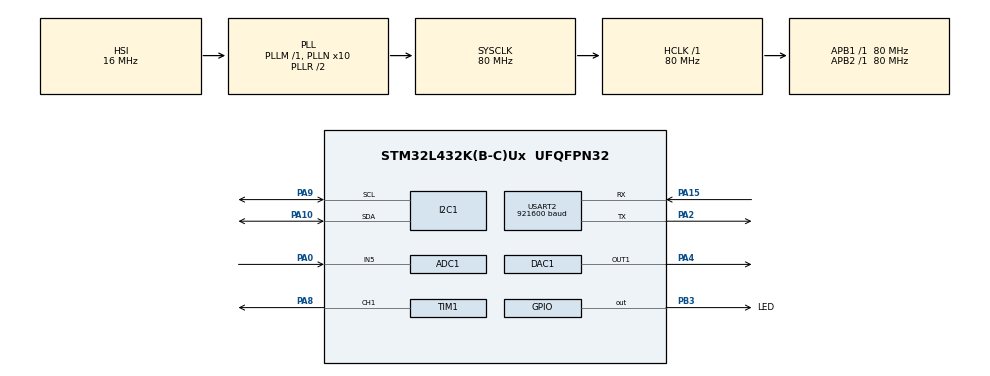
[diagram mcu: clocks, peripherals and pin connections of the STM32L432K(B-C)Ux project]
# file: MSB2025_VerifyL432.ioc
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ADC1.Channel-0\#ChannelRegularConversion=ADC_CHANNEL_5
ADC1.ClockPrescaler=ADC_CLOCK_ASYNC_DIV1
ADC1.ContinuousConvMode=ENABLE
ADC1.NbrOfConversion=1
ADC1.NbrOfConversionFlag=1
ADC1.OffsetNumber-0\#ChannelRegularConversion=ADC_OFFSET_NONE
ADC1.Rank-0\#ChannelRegularConversion=1
ADC1.SamplingTime-0\#ChannelRegularConversion=ADC_SAMPLETIME_47CYCLES_5
ADC1.master=1
DAC1.DAC_OutputBuffer-DAC_OUT1=DAC_OUTPUTBUFFER_DISABLE
DAC1.DAC_Trigger-DAC_OUT1=DAC_TRIGGER_T6_TRGO
Dma.ADC1.0.Direction=DMA_PERIPH_TO_MEMORY
Dma.ADC1.0.Instance=DMA1_Channel1
Dma.ADC1.0.MemDataAlignment=DMA_MDATAALIGN_HALFWORD
Dma.ADC1.0.MemInc=DMA_MINC_ENABLE
Dma.ADC1.0.Mode=DMA_CIRCULAR
Dma.ADC1.0.PeriphDataAlignment=DMA_PDATAALIGN_HALFWORD
Dma.ADC1.0.PeriphInc=DMA_PINC_DISABLE
Dma.ADC1.0.Priority=DMA_PRIORITY_LOW
Dma.DAC_CH1.1.Direction=DMA_MEMORY_TO_PERIPH
Dma.DAC_CH1.1.Instance=DMA2_Channel4
Dma.DAC_CH1.1.MemDataAlignment=DMA_MDATAALIGN_HALFWORD
Dma.DAC_CH1.1.MemInc=DMA_MINC_ENABLE
Dma.DAC_CH1.1.Mode=DMA_CIRCULAR
Dma.DAC_CH1.1.PeriphDataAlignment=DMA_PDATAALIGN_HALFWORD
Dma.DAC_CH1.1.PeriphInc=DMA_PINC_DISABLE
Dma.DAC_CH1.1.Priority=DMA_PRIORITY_LOW
Dma.Request0=ADC1
Dma.Request1=DAC_CH1
I2C1.Timing=0x10909CEC
Mcu.Family=STM32L4
Mcu.Name=STM32L432K(B-C)Ux
Mcu.Package=UFQFPN32
NVIC.ADC1_IRQn=true\:3\:0\:true\:false\:true\:true\:true\:true
NVIC.DMA1_Channel1_IRQn=true\:3\:0\:true\:false\:true\:false\:true\:true
NVIC.DMA2_Channel4_IRQn=true\:3\:0\:true\:false\:true\:false\:true\:true
NVIC.PriorityGroup=NVIC_PRIORITYGROUP_4
NVIC.TIM6_DAC_IRQn=true\:3\:0\:true\:false\:true\:true\:true\:true
PA0.Signal=ADCx_IN5
PA10.Mode=I2C
PA10.Signal=I2C1_SDA
PA13\ (JTMS-SWDIO).Mode=Serial_Wire
PA13\ (JTMS-SWDIO).Signal=SYS_JTMS-SWDIO
PA14\ (JTCK-SWCLK).Mode=Serial_Wire
PA14\ (JTCK-SWCLK).Signal=SYS_JTCK-SWCLK
PA15\ (JTDI).Mode=Asynchronous
PA15\ (JTDI).Signal=USART2_RX
PA2.Mode=Asynchronous
PA2.Signal=USART2_TX
PA4.Signal=COMP_DAC11_group
PA8.Signal=S_TIM1_CH1
PA9.Mode=I2C
PA9.Signal=I2C1_SCL
PB3\ (JTDO-TRACESWO).GPIO_Label=LED
PB3\ (JTDO-TRACESWO).Signal=GPIO_Output
PC14-OSC32_IN\ (PC14).Mode=LSE-External-Oscillator
PC14-OSC32_IN\ (PC14).Signal=RCC_OSC32_IN
PC15-OSC32_OUT\ (PC15).Mode=LSE-External-Oscillator
PC15-OSC32_OUT\ (PC15).Signal=RCC_OSC32_OUT
ProjectManager.HeapSize=0x200
ProjectManager.StackSize=0x400
ProjectManager.TargetToolchain=MDK-ARM V5.32
RCC.ADCFreq_Value=80000000
RCC.AHBFreq_Value=80000000
RCC.APB1Freq_Value=80000000
RCC.APB1TimFreq_Value=80000000
RCC.APB2Freq_Value=80000000
RCC.APB2TimFreq_Value=80000000
RCC.CortexFreq_Value=80000000
RCC.HCLKFreq_Value=80000000
RCC.HSE_VALUE=8000000
RCC.HSI48_VALUE=48000000
RCC.HSI_VALUE=16000000
RCC.MSI_VALUE=4000000
RCC.PLLN=10
RCC.PLLSAI1N=10
RCC.PLLSourceVirtual=RCC_PLLSOURCE_HSI
RCC.SYSCLKFreq_VALUE=80000000
RCC.SYSCLKSource=RCC_SYSCLKSOURCE_PLLCLK
RCC.USBFreq_Value=80000000
RCC.VCOOutputFreq_Value=160000000
SH.ADCx_IN5.0=ADC1_IN5,IN5-Single-Ended
SH.COMP_DAC11_group.0=DAC1_OUT1,DAC_OUT1
SH.S_TIM1_CH1.0=TIM1_CH1,PWM Generation1 CH1
TIM1.Channel-PWM\ Generation1\ CH1=TIM_CHANNEL_1
TIM1.Period=100 - 1
TIM1.Prescaler=8 - 1
TIM1.Pulse-PWM\ Generation1\ CH1=50
TIM6.AutoReloadPreload=TIM_AUTORELOAD_PRELOAD_ENABLE
TIM6.Period=60 - 1
TIM6.Prescaler=4 - 1
TIM6.TIM_MasterOutputTrigger=TIM_TRGO_UPDATE
USART2.BaudRate=921600
USART2.VirtualMode-Asynchronous=VM_ASYNC
VP_TIM1_VS_ClockSourceINT.Mode=Internal
VP_TIM6_VS_ClockSourceINT.Mode=Enable_Timer
board=custom

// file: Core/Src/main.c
/* USER CODE BEGIN Header */
/**
  ******************************************************************************
  * @file           : main.c
  * @brief          : Main program body
  ******************************************************************************
  * @attention
  *
  * Copyright (c) 2025 STMicroelectronics.
  * All rights reserved.
  *
  * This software is licensed under terms that can be found in the LICENSE file
  * in the root directory of this software component.
  * If no LICENSE file comes with this software, it is provided AS-IS.
  *
  ******************************************************************************
  */
/* USER CODE END Header */
#include "main.h"
#include "adc.h"
#include "dac.h"
#include "dma.h"
#include "i2c.h"
#include "tim.h"
#include "usart.h"
#include "gpio.h"

/* USER CODE BEGIN Includes */
#include "tasks.h"
#include "uart.h"
/* USER CODE END Includes */

void SystemClock_Config(void);

int main(void)
{

  /* MCU Configuration--------------------------------------------------------*/

  /* Reset of all peripherals, Initializes the Flash interface and the Systick. */
  HAL_Init();

  /* Configure the system clock */
  SystemClock_Config();

  /* Initialize all configured peripherals */
  MX_GPIO_Init();
  MX_DMA_Init();
  MX_ADC1_Init();
  MX_DAC1_Init();
  MX_I2C1_Init();
  MX_USART2_UART_Init();
  MX_TIM1_Init();
  MX_TIM6_Init();
  /* USER CODE BEGIN 2 */
  startup();
  HAL_TIM_Base_Start(&htim1);
  HAL_TIM_PWM_Start(&htim1, TIM_CHANNEL_1);
  /* USER CODE END 2 */

  /* Infinite loop */
  while (1)
  {

    /* USER CODE BEGIN 3 */
	  // dac_update();
	  HAL_Delay(1000);
  }
  /* USER CODE END 3 */
}

void SystemClock_Config(void)
{
  RCC_OscInitTypeDef RCC_OscInitStruct = {0};
  RCC_ClkInitTypeDef RCC_ClkInitStruct = {0};

  /** Configure the main internal regulator output voltage
  */
  if (HAL_PWREx_ControlVoltageScaling(PWR_REGULATOR_VOLTAGE_SCALE1) != HAL_OK)
  {
    Error_Handler();
  }

  /** Initializes the RCC Oscillators according to the specified parameters
  * in the RCC_OscInitTypeDef structure.
  */
  RCC_OscInitStruct.OscillatorType = RCC_OSCILLATORTYPE_HSI;
  RCC_OscInitStruct.HSIState = RCC_HSI_ON;
  RCC_OscInitStruct.HSICalibrationValue = RCC_HSICALIBRATION_DEFAULT;
  RCC_OscInitStruct.PLL.PLLState = RCC_PLL_ON;
  RCC_OscInitStruct.PLL.PLLSource = RCC_PLLSOURCE_HSI;
  RCC_OscInitStruct.PLL.PLLM = 1;
  RCC_OscInitStruct.PLL.PLLN = 10;
  RCC_OscInitStruct.PLL.PLLP = RCC_PLLP_DIV7;
  RCC_OscInitStruct.PLL.PLLQ = RCC_PLLQ_DIV2;
  RCC_OscInitStruct.PLL.PLLR = RCC_PLLR_DIV2;
  if (HAL_RCC_OscConfig(&RCC_OscInitStruct) != HAL_OK)
  {
    Error_Handler();
  }

  /** Initializes the CPU, AHB and APB buses clocks
  */
  RCC_ClkInitStruct.ClockType = RCC_CLOCKTYPE_HCLK|RCC_CLOCKTYPE_SYSCLK
                              |RCC_CLOCKTYPE_PCLK1|RCC_CLOCKTYPE_PCLK2;
  RCC_ClkInitStruct.SYSCLKSource = RCC_SYSCLKSOURCE_PLLCLK;
  RCC_ClkInitStruct.AHBCLKDivider = RCC_SYSCLK_DIV1;
  RCC_ClkInitStruct.APB1CLKDivider = RCC_HCLK_DIV1;
  RCC_ClkInitStruct.APB2CLKDivider = RCC_HCLK_DIV1;

  if (HAL_RCC_ClockConfig(&RCC_ClkInitStruct, FLASH_LATENCY_4) != HAL_OK)
  {
    Error_Handler();
  }
}

void Error_Handler(void)
{
  __disable_irq();
  while (1)
  {
  }
}
